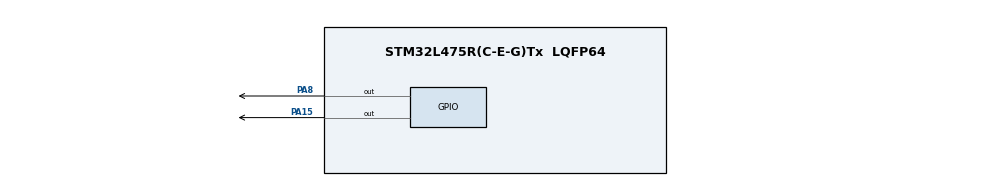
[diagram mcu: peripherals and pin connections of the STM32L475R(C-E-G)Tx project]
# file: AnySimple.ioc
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Mcu.Family=STM32L4
Mcu.Name=STM32L475R(C-E-G)Tx
Mcu.Package=LQFP64
NVIC.PriorityGroup=NVIC_PRIORITYGROUP_4
PA15\ (JTDI).Signal=GPIO_Output
PA8.Signal=GPIO_Output
ProjectManager.HeapSize=0x200
ProjectManager.StackSize=0x400
ProjectManager.TargetToolchain=TrueSTUDIO
RCC.HSE_VALUE=8000000
RCC.HSI_VALUE=16000000
RCC.LSE_VALUE=32768
RCC.MSI_VALUE=4000000
RCC.VCOOutputFreq_Value=32000000
board=custom

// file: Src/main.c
/* USER CODE BEGIN Header */
/**
  ******************************************************************************
  * @file           : main.c
  * @brief          : Main program body
  ******************************************************************************
  * @attention
  *
  * <h2><center>&copy; Copyright (c) 2019 STMicroelectronics.
  * All rights reserved.</center></h2>
  *
  * This software component is licensed by ST under BSD 3-Clause license,
  * the "License"; You may not use this file except in compliance with the
  * License. You may obtain a copy of the License at:
  *                        opensource.org/licenses/BSD-3-Clause
  *
  ******************************************************************************
  */
/* USER CODE END Header */

#include "main.h"

void SystemClock_Config(void);
static void MX_GPIO_Init(void);

/* USER CODE BEGIN 0 */
//адреса
#define MAIN_PROGRAM_START_ADDRESS 0x08010000
#define MAIN_PROGRAM_END_ADDRESS 0x08080000
//ключи
static const uint8_t AES_FW_KEY[] = {0xAF, 0xAF, 0xAF, 0xAF, 0xAF, 0xAF, 0xAF, 0xAF, 0xAF, 0xAF, 0xAF, 0xAF, 0xAF, 0xAF, 0xAF, 0xAF};
static const uint8_t AES_IV[] = {0xFA, 0xFA, 0xFA, 0xFA, 0xFA, 0xFA, 0xFA, 0xFA, 0xFA, 0xFA, 0xFA, 0xFA, 0xFA, 0xFA, 0xFA, 0xFA};
//состояния конечного автомата
#define FW_START 5
#define FW_READ 1000
#define FW_WRITE 2000
#define FW_FINISH 10000
#define FW_ERROR 100000
/* USER CODE END 0 */

int main(void)
{

  /* MCU Configuration--------------------------------------------------------*/

  /* Reset of all peripherals, Initializes the Flash interface and the Systick. */
  HAL_Init();

  /* Configure the system clock */
  SystemClock_Config();

  /* Initialize all configured peripherals */
  MX_GPIO_Init();

  /* Infinite loop */
  /* USER CODE BEGIN WHILE */
  HAL_GPIO_WritePin(GPIOA, GPIO_PIN_8, GPIO_PIN_SET);
  while (1)
  {
	  HAL_GPIO_TogglePin(GPIOA, GPIO_PIN_8);
	  HAL_GPIO_TogglePin(GPIOA, GPIO_PIN_15);
	  HAL_Delay(100);
    /* USER CODE END WHILE */

  }
}

void SystemClock_Config(void)
{
  RCC_OscInitTypeDef RCC_OscInitStruct = {0};
  RCC_ClkInitTypeDef RCC_ClkInitStruct = {0};

  /** Initializes the CPU, AHB and APB busses clocks
  */
  RCC_OscInitStruct.OscillatorType = RCC_OSCILLATORTYPE_MSI;
  RCC_OscInitStruct.MSIState = RCC_MSI_ON;
  RCC_OscInitStruct.MSICalibrationValue = 0;
  RCC_OscInitStruct.MSIClockRange = RCC_MSIRANGE_6;
  RCC_OscInitStruct.PLL.PLLState = RCC_PLL_NONE;
  if (HAL_RCC_OscConfig(&RCC_OscInitStruct) != HAL_OK)
  {
    Error_Handler();
  }
  /** Initializes the CPU, AHB and APB busses clocks
  */
  RCC_ClkInitStruct.ClockType = RCC_CLOCKTYPE_HCLK|RCC_CLOCKTYPE_SYSCLK
                              |RCC_CLOCKTYPE_PCLK1|RCC_CLOCKTYPE_PCLK2;
  RCC_ClkInitStruct.SYSCLKSource = RCC_SYSCLKSOURCE_MSI;
  RCC_ClkInitStruct.AHBCLKDivider = RCC_SYSCLK_DIV1;
  RCC_ClkInitStruct.APB1CLKDivider = RCC_HCLK_DIV1;
  RCC_ClkInitStruct.APB2CLKDivider = RCC_HCLK_DIV1;

  if (HAL_RCC_ClockConfig(&RCC_ClkInitStruct, FLASH_LATENCY_0) != HAL_OK)
  {
    Error_Handler();
  }
  /** Configure the main internal regulator output voltage
  */
  if (HAL_PWREx_ControlVoltageScaling(PWR_REGULATOR_VOLTAGE_SCALE1) != HAL_OK)
  {
    Error_Handler();
  }
}

static void MX_GPIO_Init(void)
{
  GPIO_InitTypeDef GPIO_InitStruct = {0};

  /* GPIO Ports Clock Enable */
  __HAL_RCC_GPIOA_CLK_ENABLE();

  /*Configure GPIO pin Output Level */
  HAL_GPIO_WritePin(GPIOA, GPIO_PIN_8|GPIO_PIN_15, GPIO_PIN_RESET);

  /*Configure GPIO pins : PA8 PA15 */
  GPIO_InitStruct.Pin = GPIO_PIN_8|GPIO_PIN_15;
  GPIO_InitStruct.Mode = GPIO_MODE_OUTPUT_PP;
  GPIO_InitStruct.Pull = GPIO_NOPULL;
  GPIO_InitStruct.Speed = GPIO_SPEED_FREQ_LOW;
  HAL_GPIO_Init(GPIOA, &GPIO_InitStruct);

}

void Error_Handler(void)
{
}

/************************ (C) COPYRIGHT STMicroelectronics *****END OF FILE****/
